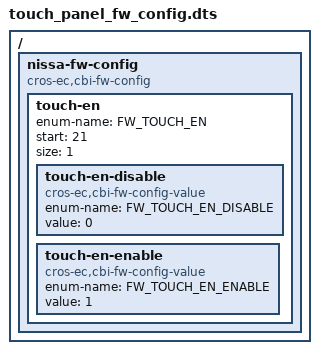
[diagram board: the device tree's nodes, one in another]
/* Copyright 2026 The ChromiumOS Authors
 * Use of this source code is governed by a BSD-style license that can be
 * found in the LICENSE file.
 */

/ {
	nissa-fw-config {
		compatible = "cros-ec,cbi-fw-config";

		touch-en {
			enum-name = "FW_TOUCH_EN";
			start = <21>;
			size = <1>;

			touch-en-disable {
				compatible = "cros-ec,cbi-fw-config-value";
				enum-name = "FW_TOUCH_EN_DISABLE";
				value = <0>;
			};
			touch-en-enable {
				compatible = "cros-ec,cbi-fw-config-value";
				enum-name = "FW_TOUCH_EN_ENABLE";
				value = <1>;
			};
		};
	};
};
